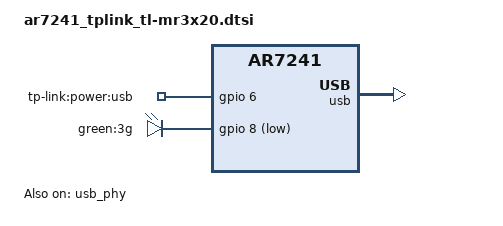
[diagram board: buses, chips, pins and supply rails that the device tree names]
// SPDX-License-Identifier: GPL-2.0-or-later OR MIT

#include "ar7241_tplink.dtsi"

/ {
	gpio-export {
		compatible = "gpio-export";
		#size-cells = <0>;

		gpio_usb_power {
			gpio-export,name = "tp-link:power:usb";
			gpio-export,output = <1>;
			gpios = <&gpio 6 GPIO_ACTIVE_HIGH>;
		};
	};
};

&leds {
	led3g {
		label = "green:3g";
		gpios = <&gpio 8 GPIO_ACTIVE_LOW>;
		trigger-sources = <&hub_port>;
		linux,default-trigger = "usbport";
	};
};

&usb {
	#address-cells = <1>;
	#size-cells = <0>;
	status = "okay";

	hub_port: port@1 {
		reg = <1>;
		#trigger-source-cells = <0>;
	};
};

&usb_phy {
	status = "okay";
};
